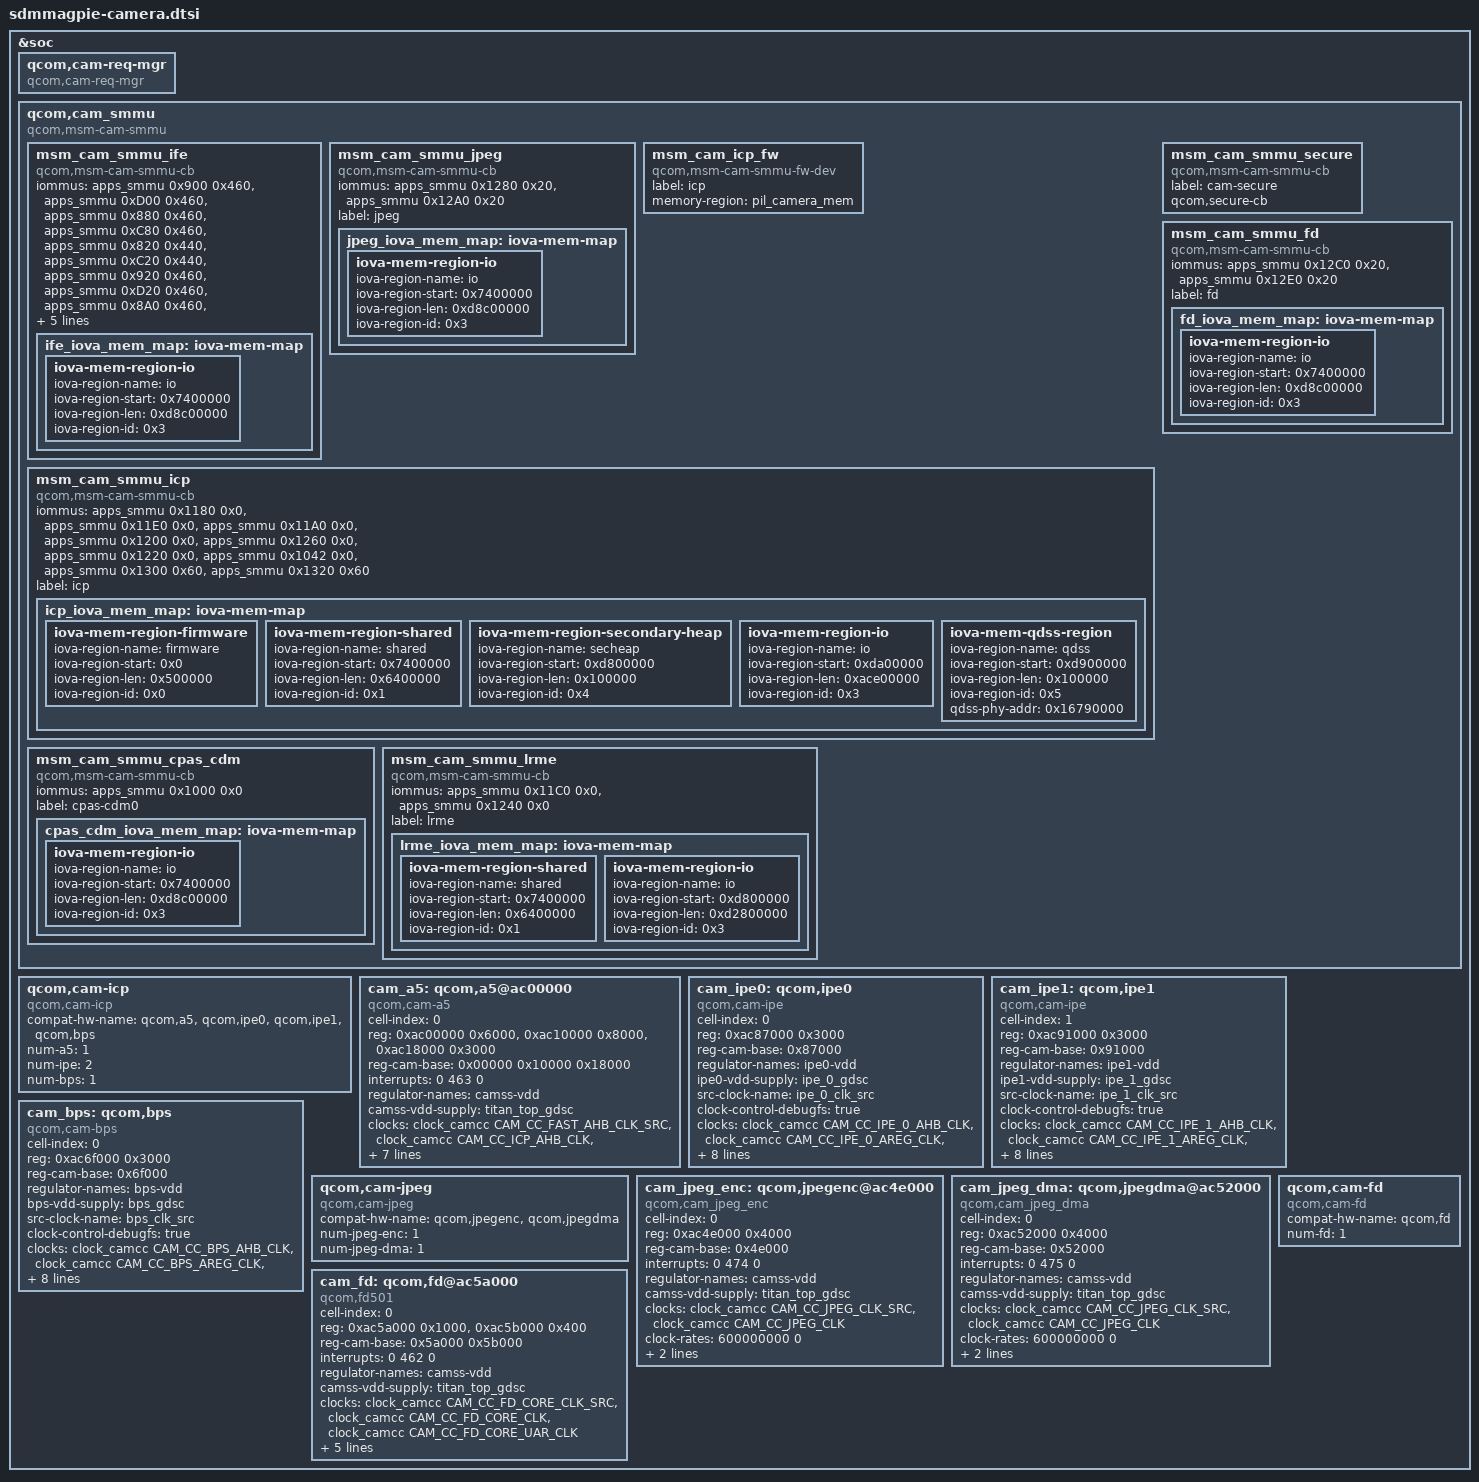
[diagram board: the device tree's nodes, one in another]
/*
 * Copyright (c) 2018, The Linux Foundation. All rights reserved.
 *
 * This program is free software; you can redistribute it and/or modify
 * it under the terms of the GNU General Public License version 2 and
 * only version 2 as published by the Free Software Foundation.
 *
 * This program is distributed in the hope that it will be useful,
 * but WITHOUT ANY WARRANTY; without even the implied warranty of
 * MERCHANTABILITY or FITNESS FOR A PARTICULAR PURPOSE.  See the
 * GNU General Public License for more details.
 */

&soc {
	qcom,cam-req-mgr {
		compatible = "qcom,cam-req-mgr";
		status = "ok";
	};

	qcom,cam_smmu {
		compatible = "qcom,msm-cam-smmu";
		status = "ok";

		msm_cam_smmu_ife {
			compatible = "qcom,msm-cam-smmu-cb";
			iommus = <&apps_smmu 0x900 0x460>,
				<&apps_smmu 0xD00 0x460>,
				<&apps_smmu 0x880 0x460>,
				<&apps_smmu 0xC80 0x460>,
				<&apps_smmu 0x820 0x440>,
				<&apps_smmu 0xC20 0x440>,
				<&apps_smmu 0x920 0x460>,
				<&apps_smmu 0xD20 0x460>,
				<&apps_smmu 0x8A0 0x460>,
				<&apps_smmu 0xCA0 0x460>,
				<&apps_smmu 0x940 0x460>,
				<&apps_smmu 0xD40 0x460>,
				<&apps_smmu 0x8C0 0x460>,
				<&apps_smmu 0xCC0 0x460>;
			label = "ife";
			ife_iova_mem_map: iova-mem-map {
				/* IO region is approximately 3.4 GB */
				iova-mem-region-io {
					iova-region-name = "io";
					iova-region-start = <0x7400000>;
					iova-region-len = <0xd8c00000>;
					iova-region-id = <0x3>;
					status = "ok";
				};
			};
		};

		msm_cam_smmu_jpeg {
			compatible = "qcom,msm-cam-smmu-cb";
			iommus = <&apps_smmu 0x1280 0x20>,
				<&apps_smmu 0x12A0 0x20>;
			label = "jpeg";
			jpeg_iova_mem_map: iova-mem-map {
				/* IO region is approximately 3.4 GB */
				iova-mem-region-io {
					iova-region-name = "io";
					iova-region-start = <0x7400000>;
					iova-region-len = <0xd8c00000>;
					iova-region-id = <0x3>;
					status = "ok";
				};
			};
		};

		msm_cam_icp_fw {
			compatible = "qcom,msm-cam-smmu-fw-dev";
			label="icp";
			memory-region = <&pil_camera_mem>;
		};

		msm_cam_smmu_icp {
			compatible = "qcom,msm-cam-smmu-cb";
			iommus = <&apps_smmu 0x1180 0x0>,
				<&apps_smmu 0x11E0 0x0>,
				<&apps_smmu 0x11A0 0x0>,
				<&apps_smmu 0x1200 0x0>,
				<&apps_smmu 0x1260 0x0>,
				<&apps_smmu 0x1220 0x0>,
				<&apps_smmu 0x1042 0x0>,
				<&apps_smmu 0x1300 0x60>,
				<&apps_smmu 0x1320 0x60>;
			label = "icp";
			icp_iova_mem_map: iova-mem-map {
				iova-mem-region-firmware {
					/* Firmware region is 5MB */
					iova-region-name = "firmware";
					iova-region-start = <0x0>;
					iova-region-len = <0x500000>;
					iova-region-id = <0x0>;
					status = "ok";
				};

				iova-mem-region-shared {
					/* Shared region is 100MB long */
					iova-region-name = "shared";
					iova-region-start = <0x7400000>;
					iova-region-len = <0x6400000>;
					iova-region-id = <0x1>;
					status = "ok";
				};

				iova-mem-region-secondary-heap {
					/* Secondary heap region is 1MB long */
					iova-region-name = "secheap";
					iova-region-start = <0xd800000>;
					iova-region-len = <0x100000>;
					iova-region-id = <0x4>;
					status = "ok";
				};

				iova-mem-region-io {
					/* IO region is approximately 3 GB */
					iova-region-name = "io";
					iova-region-start = <0xda00000>;
					iova-region-len = <0xace00000>;
					iova-region-id = <0x3>;
					status = "ok";
				};

				iova-mem-qdss-region {
					/* QDSS region is appropriate 1MB */
					iova-region-name = "qdss";
					iova-region-start = <0xd900000>;
					iova-region-len = <0x100000>;
					iova-region-id = <0x5>;
					qdss-phy-addr = <0x16790000>;
					status = "ok";
				};
			};
		};

		msm_cam_smmu_cpas_cdm {
			compatible = "qcom,msm-cam-smmu-cb";
			iommus = <&apps_smmu 0x1000 0x0>;
			label = "cpas-cdm0";
			cpas_cdm_iova_mem_map: iova-mem-map {
				iova-mem-region-io {
					/* IO region is approximately 3.4 GB */
					iova-region-name = "io";
					iova-region-start = <0x7400000>;
					iova-region-len = <0xd8c00000>;
					iova-region-id = <0x3>;
					status = "ok";
				};
			};
		};

		msm_cam_smmu_secure {
			compatible = "qcom,msm-cam-smmu-cb";
			label = "cam-secure";
			qcom,secure-cb;
		};

		msm_cam_smmu_fd {
			compatible = "qcom,msm-cam-smmu-cb";
			iommus = <&apps_smmu 0x12C0 0x20>,
				<&apps_smmu 0x12E0 0x20>;
			label = "fd";
			fd_iova_mem_map: iova-mem-map {
				iova-mem-region-io {
					/* IO region is approximately 3.4 GB */
					iova-region-name = "io";
					iova-region-start = <0x7400000>;
					iova-region-len = <0xd8c00000>;
					iova-region-id = <0x3>;
					status = "ok";
				};
			};
		};

		msm_cam_smmu_lrme {
			compatible = "qcom,msm-cam-smmu-cb";
			iommus = <&apps_smmu 0x11C0 0x0>,
				<&apps_smmu 0x1240 0x0>;
			label = "lrme";
			lrme_iova_mem_map: iova-mem-map {
				iova-mem-region-shared {
					/* Shared region is 100MB long */
					iova-region-name = "shared";
					iova-region-start = <0x7400000>;
					iova-region-len = <0x6400000>;
					iova-region-id = <0x1>;
					status = "ok";
				};
				/* IO region is approximately 3.3 GB */
				iova-mem-region-io {
					iova-region-name = "io";
					iova-region-start = <0xd800000>;
					iova-region-len = <0xd2800000>;
					iova-region-id = <0x3>;
					status = "ok";
				};
			};
		};
	};

	qcom,cam-icp {
		compatible = "qcom,cam-icp";
		compat-hw-name = "qcom,a5",
			"qcom,ipe0",
			"qcom,ipe1",
			"qcom,bps";
		num-a5 = <1>;
		num-ipe = <2>;
		num-bps = <1>;
		status = "ok";
	};

	cam_a5: qcom,a5@ac00000 {
		cell-index = <0>;
		compatible = "qcom,cam-a5";
		reg = <0xac00000 0x6000>,
			<0xac10000 0x8000>,
			<0xac18000 0x3000>;
		reg-names = "a5_qgic", "a5_sierra", "a5_csr";
		reg-cam-base = <0x00000 0x10000 0x18000>;
		interrupts = <0 463 0>;
		interrupt-names = "a5";
		regulator-names = "camss-vdd";
		camss-vdd-supply = <&titan_top_gdsc>;
		clock-names =
			"soc_fast_ahb",
			"icp_ahb_clk",
			"icp_clk_src",
			"icp_clk";
		clocks =
			<&clock_camcc CAM_CC_FAST_AHB_CLK_SRC>,
			<&clock_camcc CAM_CC_ICP_AHB_CLK>,
			<&clock_camcc CAM_CC_ICP_CLK_SRC>,
			<&clock_camcc CAM_CC_ICP_CLK>;

		clock-rates =
			<200000000 0 400000000 0>,
			<400000000 0 600000000 0>;
		clock-cntl-level = "svs", "turbo";
		fw_name = "CAMERA_ICP.elf";
		ubwc-cfg = <0x73 0x1CF>;
		status = "ok";
	};

	cam_ipe0: qcom,ipe0 {
		cell-index = <0>;
		compatible = "qcom,cam-ipe";
		reg = <0xac87000 0x3000>;
		reg-names = "ipe0_top";
		reg-cam-base = <0x87000>;
		regulator-names = "ipe0-vdd";
		ipe0-vdd-supply = <&ipe_0_gdsc>;
		clock-names =
			"ipe_0_ahb_clk",
			"ipe_0_areg_clk",
			"ipe_0_axi_clk",
			"ipe_0_clk_src",
			"ipe_0_clk";
		src-clock-name = "ipe_0_clk_src";
		clock-control-debugfs = "true";
		clocks =
			<&clock_camcc CAM_CC_IPE_0_AHB_CLK>,
			<&clock_camcc CAM_CC_IPE_0_AREG_CLK>,
			<&clock_camcc CAM_CC_IPE_0_AXI_CLK>,
			<&clock_camcc CAM_CC_IPE_0_CLK_SRC>,
			<&clock_camcc CAM_CC_IPE_0_CLK>;

		clock-rates =
			<0 0 0 340000000 0>,
			<0 0 0 430000000 0>,
			<0 0 0 520000000 0>,
			<0 0 0 600000000 0>,
			<0 0 0 600000000 0>;
		clock-cntl-level = "lowsvs", "svs", "svs_l1",
				"nominal", "turbo";
		status = "ok";
	};

	cam_ipe1: qcom,ipe1 {
		cell-index = <1>;
		compatible = "qcom,cam-ipe";
		reg = <0xac91000 0x3000>;
		reg-names = "ipe1_top";
		reg-cam-base = <0x91000>;
		regulator-names = "ipe1-vdd";
		ipe1-vdd-supply = <&ipe_1_gdsc>;
		clock-names =
			"ipe_1_ahb_clk",
			"ipe_1_areg_clk",
			"ipe_1_axi_clk",
			"ipe_1_clk_src",
			"ipe_1_clk";
		src-clock-name = "ipe_1_clk_src";
		clock-control-debugfs = "true";
		clocks =
			<&clock_camcc CAM_CC_IPE_1_AHB_CLK>,
			<&clock_camcc CAM_CC_IPE_1_AREG_CLK>,
			<&clock_camcc CAM_CC_IPE_1_AXI_CLK>,
			<&clock_camcc CAM_CC_IPE_0_CLK_SRC>,
			<&clock_camcc CAM_CC_IPE_1_CLK>;

		clock-rates =
			<0 0 0 340000000 0>,
			<0 0 0 430000000 0>,
			<0 0 0 520000000 0>,
			<0 0 0 600000000 0>,
			<0 0 0 600000000 0>;
		clock-cntl-level = "lowsvs", "svs", "svs_l1",
				"nominal", "turbo";
		status = "ok";
	};

	cam_bps: qcom,bps {
		cell-index = <0>;
		compatible = "qcom,cam-bps";
		reg = <0xac6f000 0x3000>;
		reg-names = "bps_top";
		reg-cam-base = <0x6f000>;
		regulator-names = "bps-vdd";
		bps-vdd-supply = <&bps_gdsc>;
		clock-names =
			"bps_ahb_clk",
			"bps_areg_clk",
			"bps_axi_clk",
			"bps_clk_src",
			"bps_clk";
		src-clock-name = "bps_clk_src";
		clock-control-debugfs = "true";
		clocks =
			<&clock_camcc CAM_CC_BPS_AHB_CLK>,
			<&clock_camcc CAM_CC_BPS_AREG_CLK>,
			<&clock_camcc CAM_CC_BPS_AXI_CLK>,
			<&clock_camcc CAM_CC_BPS_CLK_SRC>,
			<&clock_camcc CAM_CC_BPS_CLK>;

		clock-rates =
			<0 0 0 200000000 0>,
			<0 0 0 400000000 0>,
			<0 0 0 480000000 0>,
			<0 0 0 600000000 0>,
			<0 0 0 600000000 0>;
		clock-cntl-level = "lowsvs", "svs", "svs_l1",
				"nominal", "turbo";
		status = "ok";
	};

	qcom,cam-jpeg {
		compatible = "qcom,cam-jpeg";
		compat-hw-name = "qcom,jpegenc",
			"qcom,jpegdma";
		num-jpeg-enc = <1>;
		num-jpeg-dma = <1>;
		status = "ok";
	};

	cam_jpeg_enc: qcom,jpegenc@ac4e000 {
		cell-index = <0>;
		compatible = "qcom,cam_jpeg_enc";
		reg-names = "jpege_hw";
		reg = <0xac4e000 0x4000>;
		reg-cam-base = <0x4e000>;
		interrupt-names = "jpeg";
		interrupts = <0 474 0>;
		regulator-names = "camss-vdd";
		camss-vdd-supply = <&titan_top_gdsc>;
		clock-names =
			"jpegenc_clk_src",
			"jpegenc_clk";
		clocks =
			<&clock_camcc CAM_CC_JPEG_CLK_SRC>,
			<&clock_camcc CAM_CC_JPEG_CLK>;

		clock-rates = <600000000 0>;
		src-clock-name = "jpegenc_clk_src";
		clock-cntl-level = "nominal";
		status = "ok";
	};

	cam_jpeg_dma: qcom,jpegdma@ac52000{
		cell-index = <0>;
		compatible = "qcom,cam_jpeg_dma";
		reg-names = "jpegdma_hw";
		reg = <0xac52000 0x4000>;
		reg-cam-base = <0x52000>;
		interrupt-names = "jpegdma";
		interrupts = <0 475 0>;
		regulator-names = "camss-vdd";
		camss-vdd-supply = <&titan_top_gdsc>;
		clock-names =
			"jpegdma_clk_src",
			"jpegdma_clk";
		clocks =
			<&clock_camcc CAM_CC_JPEG_CLK_SRC>,
			<&clock_camcc CAM_CC_JPEG_CLK>;

		clock-rates = <600000000 0>;
		src-clock-name = "jpegdma_clk_src";
		clock-cntl-level = "nominal";
		status = "ok";
	};

	qcom,cam-fd {
		compatible = "qcom,cam-fd";
		compat-hw-name = "qcom,fd";
		num-fd = <1>;
		status = "ok";
	};

	cam_fd: qcom,fd@ac5a000 {
		cell-index = <0>;
		compatible = "qcom,fd501";
		reg-names = "fd_core", "fd_wrapper";
		reg = <0xac5a000 0x1000>,
			<0xac5b000 0x400>;
		reg-cam-base = <0x5a000 0x5b000>;
		interrupt-names = "fd";
		interrupts = <0 462 0>;
		regulator-names = "camss-vdd";
		camss-vdd-supply = <&titan_top_gdsc>;
		clock-names =
			"fd_core_clk_src",
			"fd_core_clk",
			"fd_core_uar_clk";
		clocks =
			<&clock_camcc CAM_CC_FD_CORE_CLK_SRC>,
			<&clock_camcc CAM_CC_FD_CORE_CLK>,
			<&clock_camcc CAM_CC_FD_CORE_UAR_CLK>;
		src-clock-name = "fd_core_clk_src";
		clock-control-debugfs = "true";
		clock-cntl-level = "lowsvs", "svs", "svs_l1", "turbo";
		clock-rates =
			<380000000 0 0>,
			<384000000 0 0>,
			<480000000 0 0>,
			<600000000 0 0>;
		status = "ok";
	};
};
